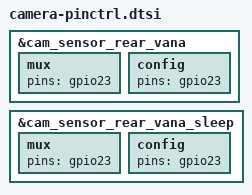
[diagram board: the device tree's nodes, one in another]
/* msm8953-pinctrl.dtsi */
&cam_sensor_rear_vana {
	mux {
		pins = "gpio23";
	};

	config {
		pins = "gpio23";
	};
};
&cam_sensor_rear_vana_sleep {
	mux {
		pins = "gpio23";
	};

	config {
		pins = "gpio23";
	};
};
